# TMS320F280049 register map
Vendor: Texas Instruments; Series: C2000 F28004x; File version: 0.2.0-generated
Registers are 16-bit, read-write, reset 0x0 unless marked. A register's access mark holds for its fields unless they carry their own. Offsets are from the block's base; [hi:lo] are bit positions; {n}, {i} and the like mark numbered series.

## ADCAREGS — ADC Registers
Base 0x0000E800
Same registers: ADCBREGS 0x0000E900, ADCCREGS 0x0000EA00
0x00 ADCCTL1 — ADC Control 1 Register
  [13] ADCBSY — ADC Busy
  [14:11] ADCBSYCHN — ADC Busy Channel
  [7] ADCPWDNZ — ADC Power Down
  [2] INTPULSEPOS — ADC Interrupt Pulse Position
0x02 ADCCTL2 — ADC Control 2 Register
  [6:3] PRESCALE — ADC Clock Prescaler
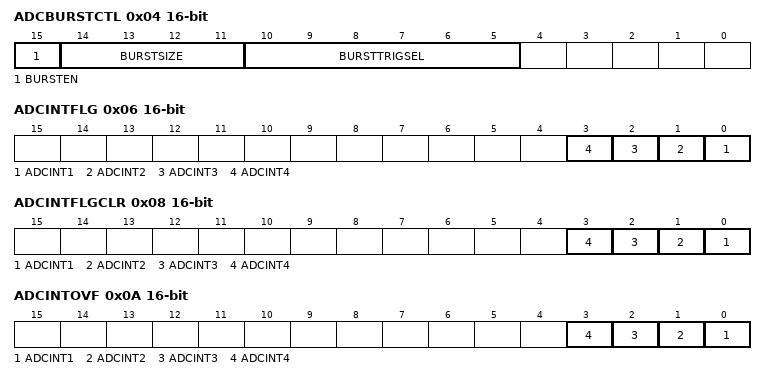
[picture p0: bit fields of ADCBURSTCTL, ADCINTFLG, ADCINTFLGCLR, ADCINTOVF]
0x04 ADCBURSTCTL — ADC Burst Control Register
  [15] BURSTEN — SOC Burst Mode Enable
  [14:11] BURSTSIZE — SOC Burst Size Select
  [10:5] BURSTTRIGSEL — SOC Burst Trigger Source Select
0x06 ADCINTFLG — ADC Interrupt Flag Register
  [n-1] ADCINT{n} (n=1..4) — ADC Interrupt {n} Flag
0x08 ADCINTFLGCLR — ADC Interrupt Flag Clear Register
  [n-1] ADCINT{n} (n=1..4) — ADC Interrupt {n} Flag Clear
0x0A ADCINTOVF — ADC Interrupt Overflow Register
  [n-1] ADCINT{n} (n=1..4) — ADC Interrupt {n} Overflow Flags
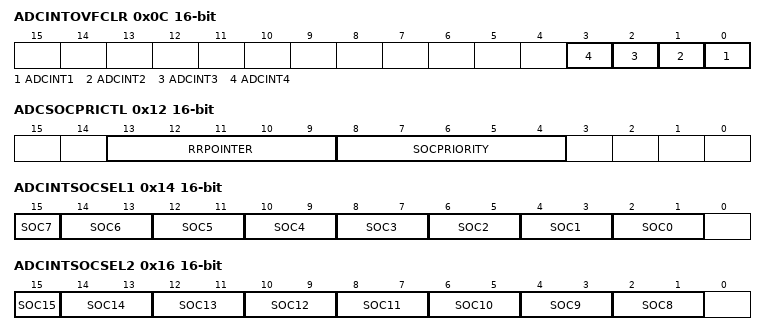
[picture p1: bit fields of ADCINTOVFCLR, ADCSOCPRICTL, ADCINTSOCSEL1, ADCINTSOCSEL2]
0x0C ADCINTOVFCLR — ADC Interrupt Overflow Clear Register
  [n-1] ADCINT{n} (n=1..4) — ADC Interrupt {n} Overflow Clear Bits
0x0E ADCINTSEL1N2 — ADC Interrupt 1 and 2 Selection Register
  [14] INT2CONT — ADCINT2 Continue to Interrupt Mode
  [13] INT2E — ADCINT2 Interrupt Enable
  [14:11] INT2SEL — ADCINT2 EOC Source Select
  [6] INT1CONT — ADCINT1 Continue to Interrupt Mode
  [5] INT1E — ADCINT1 Interrupt Enable
  [6:3] INT1SEL — ADCINT1 EOC Source Select
0x10 ADCINTSEL3N4 — ADC Interrupt 3 and 4 Selection Register
  [14] INT4CONT — ADCINT4 Continue to Interrupt Mode
  [13] INT4E — ADCINT4 Interrupt Enable
  [14:11] INT4SEL — ADCINT4 EOC Source Select
  [6] INT3CONT — ADCINT3 Continue to Interrupt Mode
  [5] INT3E — ADCINT3 Interrupt Enable
  [6:3] INT3SEL — ADCINT3 EOC Source Select
0x12 ADCSOCPRICTL — ADC SOC Priority Control Register
  [13:9] RRPOINTER — Round Robin Pointer
  [8:4] SOCPRIORITY
0x14 ADCINTSOCSEL1 — ADC Interrupt SOC Selection 1 Register
  [15] SOC7 — SOC7 ADC Interrupt Trigger Select
  [2n+2:2n+1] SOC{n} (n=0..6) — SOC{n} ADC Interrupt Trigger Select
0x16 ADCINTSOCSEL2 — ADC Interrupt SOC Selection 2 Register
  [15] SOC15 — SOC15 ADC Interrupt Trigger Select
  [2n-14:2n-15] SOC{n} (n=8..14) — SOC{n} ADC Interrupt Trigger Select
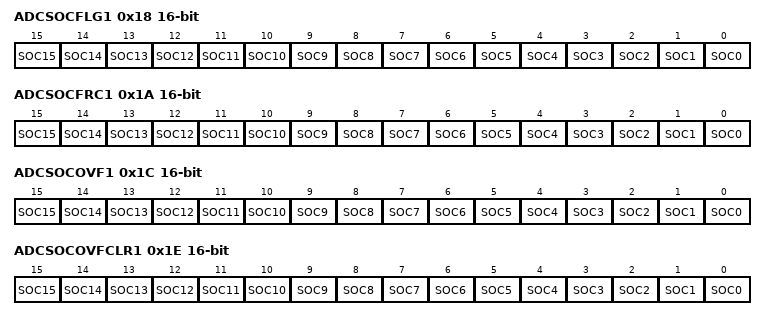
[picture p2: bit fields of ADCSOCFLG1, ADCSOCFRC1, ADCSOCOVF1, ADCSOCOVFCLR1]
0x18 ADCSOCFLG1 — ADC SOC Flag 1 Register
  [n] SOC{n} (n=0..15) — SOC{n} Start of Conversion Flag
0x1A ADCSOCFRC1 — ADC SOC Force 1 Register
  [n] SOC{n} (n=0..15) — SOC{n} Force Start of Conversion Bit
0x1C ADCSOCOVF1 — ADC SOC Overflow 1 Register
  [n] SOC{n} (n=0..15) — SOC{n} Start of Conversion Overflow Flag
0x1E ADCSOCOVFCLR1 — ADC SOC Overflow Clear 1 Register
  [n] SOC{n} (n=0..15) — SOC{n} Clear Start of Conversion Overflow Bit
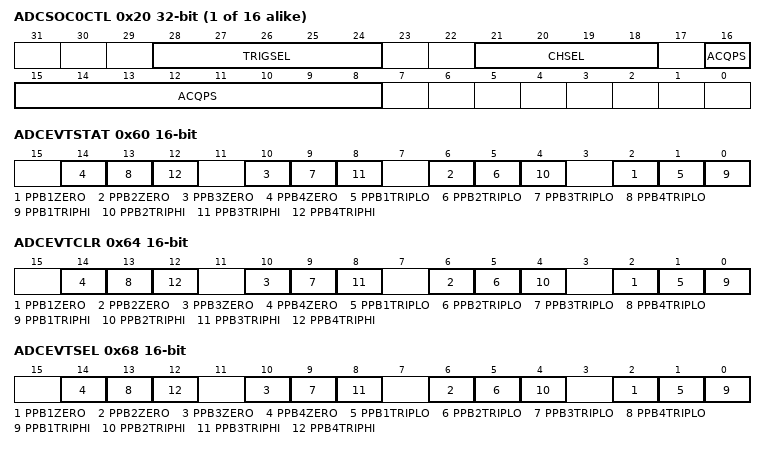
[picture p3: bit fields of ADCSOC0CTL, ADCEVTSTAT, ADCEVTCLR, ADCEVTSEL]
{0x20+4i} ADCSOC{i}CTL 32-bit (i=0..15) — ADC SOC{i} Control Register
  [28:24] TRIGSEL — SOC{i} Trigger Source Select
  [21:18] CHSEL — SOC{i} Channel Select
  [16:8] ACQPS — SOC{i} Acquisition Prescale
0x60 ADCEVTSTAT — ADC Event Status Register
  [4n-2] PPB{n}ZERO (n=1..4) — Post Processing Block {n} Zero Crossing Flag
  [4n-3] PPB{n}TRIPLO (n=1..4) — Post Processing Block {n} Trip Low Flag
  [4n-4] PPB{n}TRIPHI (n=1..4) — Post Processing Block {n} Trip High Flag
0x64 ADCEVTCLR — ADC Event Clear Register
  [4n-2] PPB{n}ZERO (n=1..4) — Post Processing Block {n} Zero Crossing Clear
  [4n-3] PPB{n}TRIPLO (n=1..4) — Post Processing Block {n} Trip Low Clear
  [4n-4] PPB{n}TRIPHI (n=1..4) — Post Processing Block {n} Trip High Clear
0x68 ADCEVTSEL — ADC Event Selection Register
  [4n-2] PPB{n}ZERO (n=1..4) — Post Processing Block {n} Zero Crossing Event Enable
  [4n-3] PPB{n}TRIPLO (n=1..4) — Post Processing Block {n} Trip Low Event Enable
  [4n-4] PPB{n}TRIPHI (n=1..4) — Post Processing Block {n} Trip High Event Enable
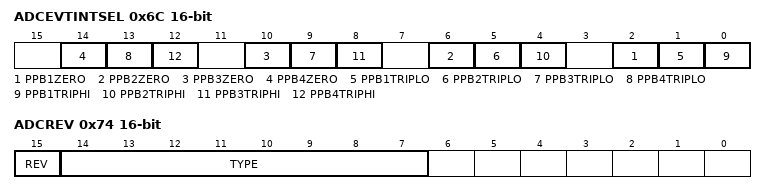
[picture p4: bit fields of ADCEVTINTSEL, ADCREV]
0x6C ADCEVTINTSEL — ADC Event Interrupt Selection Register
  [4n-2] PPB{n}ZERO (n=1..4) — Post Processing Block {n} Zero Crossing Interrupt Enable
  [4n-3] PPB{n}TRIPLO (n=1..4) — Post Processing Block {n} Trip Low Interrupt Enable
  [4n-4] PPB{n}TRIPHI (n=1..4) — Post Processing Block {n} Trip High Interrupt Enable
0x70 ADCOSDETECT — ADC Open and Shorts Detect Register
  [4:2] DETECTCFG — ADC Opens and Shorts Detect Configuration
0x72 ADCCOUNTER
  [15:11] FREECOUNT — ADC Free Running Counter Value
0x74 ADCREV — ADC Revision Register
  [15] REV — ADC Revision
  [14:7] TYPE — ADC Type
0x76 ADCOFFTRIM — ADC Offset Trim Register
  [14:7] OFFTRIM — ADC Offset Trim
{0x70+0x10*i} ADCPPB{i}CONFIG (i=1..4)
  [5] CBCEN — Cycle By Cycle Enable
  [4] TWOSCOMPEN — ADC Post Processing Block {i} Two's Complement Enable
  [6:3] CONFIG — ADC Post Processing Block {i} Configuration
{0x72+0x10*i} ADCPPB{i}STAMP (i=1..4) — ADC PPB{i} Sample Delay Time Stamp Register
  [15:11] DLYSTAMP — ADC Post Processing Block {i} Delay Time Stamp
{0x74+0x10*i} ADCPPB{i}OFFCAL (i=1..4) — ADC PPB{i} Offset Calibration Register
  [15:9] OFFCAL — ADC Post Processing Block Offset Correction
{0x76+0x10*i} ADCPPB{i}OFFREF (i=1..4) — ADC PPB{i} Offset Reference Register
  [15] OFFREF — ADC Post Processing Block {i} Offset Reference
{0x78+0x10*i} ADCPPB{i}TRIPHI 32-bit (i=1..4) — ADC PPB{i} Trip High Register
  [16] HSIGN — High Limit Sign Bit
  [30:15] LIMITHI — ADC Post Processing Block {i} Trip High Limit
{0x7C+0x10*i} ADCPPB{i}TRIPLO 32-bit (i=1..4) — ADC PPB{i} Trip Low/Trigger Time Stamp Register
  [31] REQSTAMP — ADC Post Processing Block {i} Request Time Stamp
  [16] LSIGN — Low Limit Sign Bit
  [30:15] LIMITLO — ADC Post Processing Block {i} Trip Low Limit
0xDE ADCINTCYCLE — ADC Early Interrupt Generation Cycle
  [15] DELAY — Delay from ADCSOC fall edge to early interrupt generation.
0xE4 ADCINLTRIM2 32-bit — ADC Linearity Trim 2 Register
  [31] INLTRIM63TO32 — ADC Linearity Trim Bits 63-32
0xE8 ADCINLTRIM3 32-bit — ADC Linearity Trim 3 Register
  [31] INLTRIM95TO64 — ADC Linearity Trim Bits 95-64
